# M251_v1 register map
File version: 1.0
Registers are 32-bit, read-write, reset 0x0 unless marked. A register's access mark holds for its fields unless they carry their own. Offsets are from the block's base; [hi:lo] are bit positions; {n}, {i} and the like mark numbered series.

## RTC — RTC Register Map
Base 0x40041000
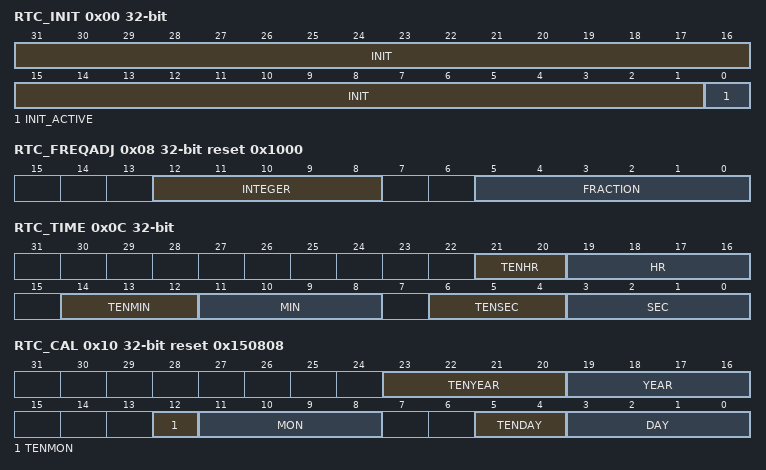
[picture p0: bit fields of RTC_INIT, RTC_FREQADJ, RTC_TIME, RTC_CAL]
0x00 RTC_INIT — RTC Initiation Register
  [31:1] INIT wo — RTC Initiation (Write Only). When RTC block is powered on, RTC is at reset state. User has to write a number (0x a5eb1357) to INIT to make RTC leave reset state. Once the INIT is written as 0xa5eb1357, the RTC will be in un-reset state permanently. The INIT is a write-only field and read value will be always 0.
  [0] INIT_ACTIVE ro — RTC Active Status (Read Only)
    0=RTC is at reset state; 1=RTC is at normal active state
0x08 RTC_FREQADJ reset 0x1000 — RTC Frequency Compensation Register
  [12:8] INTEGER — Integer Part
    {v}=Integer part of detected value is {v+32752} (v=0..31)
  [5:0] FRACTION — Fraction Part. Note: Digit in FCR must be expressed as hexadecimal number.
0x0C RTC_TIME — RTC Time Loading Register
  [21:20] TENHR — 10-Hour Time Digit (0~2)When RTC runs as 12-hour time scale mode, RTC_TIME[21] (the high bit of TENHR[1:0]) means AM/PM indication (If RTC_TIME[21] is 1, it indicates PM time message.)
  [19:16] HR — 1-Hour Time Digit (0~9)
  [14:12] TENMIN — 10-Min Time Digit (0~5)
  [11:8] MIN — 1-Min Time Digit (0~9)
  [6:4] TENSEC — 10-Sec Time Digit (0~5)
  [3:0] SEC — 1-Sec Time Digit (0~9)
0x10 RTC_CAL reset 0x150808 — RTC Calendar Loading Register
  [23:20] TENYEAR — 10-Year Calendar Digit (0~9)
  [19:16] YEAR — 1-Year Calendar Digit (0~9)
  [12] TENMON — 10-Month Calendar Digit (0~1)
  [11:8] MON — 1-Month Calendar Digit (0~9)
  [5:4] TENDAY — 10-Day Calendar Digit (0~3)
  [3:0] DAY — 1-Day Calendar Digit (0~9)
0x14 RTC_CLKFMT reset 0x1 — RTC Time Scale Selection Register
  [0] _24HEN — 24-hour / 12-hour Time Scale Selection. Indicates that RTC_TIME and RTC_TALM are in 24-hour time scale or 12-hour time scale
    0=12-hour time scale with AM and PM indication selected; 1=24-hour time scale selected
0x18 RTC_WEEKDAY reset 0x6 — RTC Day of the Week Register
  [2:0] WEEKDAY — Day of the Week Register
    0=Sunday; 1=Monday; 2=Tuesday; 3=Wednesday; 4=Thursday; 5=Friday; 6=Saturday
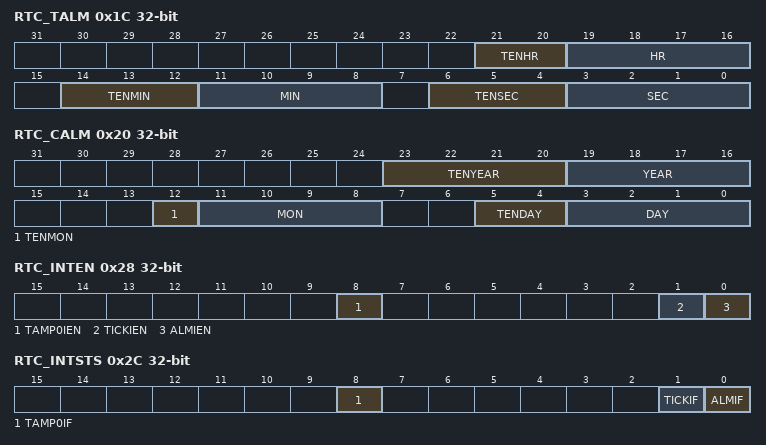
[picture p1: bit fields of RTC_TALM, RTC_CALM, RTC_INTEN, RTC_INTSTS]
0x1C RTC_TALM — RTC Time Alarm Register
  [21:20] TENHR — 10-Hour Time Digit of Alarm Setting (0~2)When RTC runs as 12-hour time scale mode, RTC_TIME[21] (the high bit of TENHR[1:0]) means AM/PM indication (If RTC_TIME[21] is 1, it indicates PM time message.)
  [19:16] HR — 1-Hour Time Digit of Alarm Setting (0~9)
  [14:12] TENMIN — 10-Min Time Digit of Alarm Setting (0~5)
  [11:8] MIN — 1-Min Time Digit of Alarm Setting (0~9)
  [6:4] TENSEC — 10-Sec Time Digit of Alarm Setting (0~5)
  [3:0] SEC — 1-Sec Time Digit of Alarm Setting (0~9)
0x20 RTC_CALM — RTC Calendar Alarm Register
  [23:20] TENYEAR — 10-Year Calendar Digit of Alarm Setting (0~9)
  [19:16] YEAR — 1-Year Calendar Digit of Alarm Setting (0~9)
  [12] TENMON — 10-Month Calendar Digit of Alarm Setting (0~1)
  [11:8] MON — 1-Month Calendar Digit of Alarm Setting (0~9)
  [5:4] TENDAY — 10-Day Calendar Digit of Alarm Setting (0~3)
  [3:0] DAY — 1-Day Calendar Digit of Alarm Setting (0~9)
0x24 RTC_LEAPYEAR ro — RTC Leap Year Indicator Register
  [0] LEAPYEAR — Leap Year Indication (Read Only)
    0=This year is not a leap year; 1=This year is leap year
0x28 RTC_INTEN — RTC Interrupt Enable Register
  [8] TAMP0IEN — Tamper 0 Interrupt Enable Bit. Set TAMP0IEN to 1 can also enable chip wake-up function when tamper 0 interrupt event is generated.
    0=Tamper 0 interrupt Disabled; 1=Tamper 0 interrupt Enabled
  [1] TICKIEN — Time Tick Interrupt Enable Bit. Set TICKIEN to 1 can also enable chip wake-up function when RTC tick interrupt event is generated.
    0=RTC Time Tick interrupt Disabled; 1=RTC Time Tick interrupt Enabled
  [0] ALMIEN — Alarm Interrupt Enable Bit. Set ALMIEN to 1 can also enable chip wake-up function when RTC alarm interrupt event is generated.
    0=RTC Alarm interrupt Disabled; 1=RTC Alarm interrupt Enabled
0x2C RTC_INTSTS — RTC Interrupt Status Register
  [8] TAMP0IF — Tamper 0 Interrupt Flag. Note: Write 1 to clear this bit.
    0=No Tamper 0 interrupt flag is generated; 1=Tamper 0 interrupt flag is generated
  [1] TICKIF — RTC Time Tick Interrupt Flag. Note: Write 1 to clear this bit.
    0=Tick condition did not occur; 1=Tick condition occurred
  [0] ALMIF — RTC Alarm Interrupt Flag. Note: Write 1 to clear this bit.
    0=Alarm condition is not matched; 1=Alarm condition is matched
0x30 RTC_TICK — RTC Time Tick Register
  [2:0] TICK — Time Tick Register. These bits are used to select RTC time tick period for Periodic Time Tick Interrupt request.
    0=Time tick is 1 second; 1=Time tick is 1/2 second; 2=Time tick is 1/4 second; 3=Time tick is 1/8 second; 4=Time tick is 1/16 second; 5=Time tick is 1/32 second; 6=Time tick is 1/64 second; 7=Time tick is 1/128 second
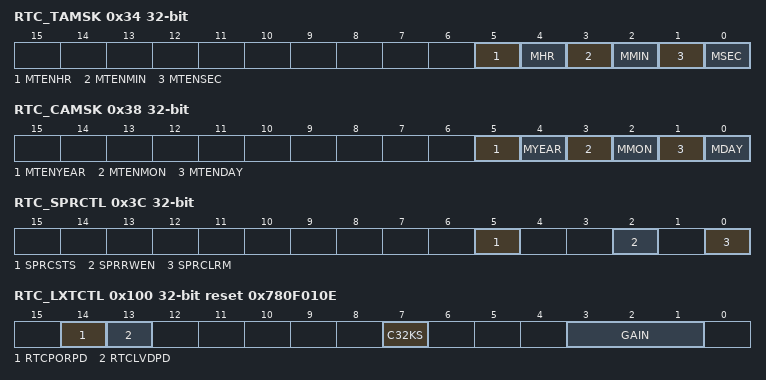
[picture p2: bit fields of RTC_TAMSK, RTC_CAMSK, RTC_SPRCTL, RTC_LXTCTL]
0x34 RTC_TAMSK — RTC Time Alarm Mask Register
  [5] MTENHR — Mask 10-Hour Time Digit of Alarm Setting (0~2)
  [4] MHR — Mask 1-Hour Time Digit of Alarm Setting (0~9)
  [3] MTENMIN — Mask 10-Min Time Digit of Alarm Setting (0~5)
  [2] MMIN — Mask 1-Min Time Digit of Alarm Setting (0~9)
  [1] MTENSEC — Mask 10-Sec Time Digit of Alarm Setting (0~5)
  [0] MSEC — Mask 1-Sec Time Digit of Alarm Setting (0~9)
0x38 RTC_CAMSK — RTC Calendar Alarm Mask Register
  [5] MTENYEAR — Mask 10-Year Calendar Digit of Alarm Setting (0~9)
  [4] MYEAR — Mask 1-Year Calendar Digit of Alarm Setting (0~9)
  [3] MTENMON — Mask 10-Month Calendar Digit of Alarm Setting (0~1)
  [2] MMON — Mask 1-Month Calendar Digit of Alarm Setting (0~9)
  [1] MTENDAY — Mask 10-Day Calendar Digit of Alarm Setting (0~3)
  [0] MDAY — Mask 1-Day Calendar Digit of Alarm Setting (0~9)
0x3C RTC_SPRCTL — RTC Spare Functional Control Register
  [5] SPRCSTS — SPR Clear Flag. This bit indicates if the RTC_SPR0 ~RTC_SPR4 content is cleared when specify tamper event is detected. Note1: Write 1 to clear this bit. Note2: This bit keeps 1 when RTC_INTSTS[8] is not equal to 0.
    0=Spare register content is not cleared; 1=Spare register content is cleared
  [2] SPRRWEN — Spare Register Enable Bit. Note: When spare register is disabled, RTC_SPR0 ~ RTC_SPR4 cannot be accessed.
    0=Spare register Disabled; 1=Spare register Enabled
  [0] SPRCLRM — Spare Register Clear Mask Bit
    0=Spare register will be clear after TAMPER occurs; 1=Spare register will not be clear after TAMPER occurs
{0x40+4i} RTC_SPR{i} (i=0..4) — RTC Spare Register {i}
  [31:0] SPARE — Spare Register. This field is used to store back-up information defined by user. This field will be cleared by hardware automatically once a tamper pin event is detected.
0x100 RTC_LXTCTL reset 0x780F010E — RTC 32.768 KHz Oscillator Control Register
  [14] RTCPORPD — RTC Power on Reset Power Down (Only for VBAT Domain). Note: This bit only can be set to 1.
    0=RTC POR active 1sec after first power up; 1=RTC POR enter power down
  [13] RTCLVDPD — RTC Low Voltage Detector Power Down (Only for VBAT Domain)
    0=RTC Low Voltage Detector active; 1=RTC Low Voltage Detector enter power down
  [7] C32KS — Clock 32K Source Selection:
    0=Internal 32K clock is from 32K crystal; 1=Internal 32K clock is from LIRC32K
  [3:1] GAIN — Oscillator Gain Option. User can select oscillator gain according to crystal external loading and operating temperature range. The larger gain value corresponding to stronger driving capability and higher power consumption. Note: Please refer to the M251 Datasheet for detailed information about LXT electrical characteristics.
    {v}=L{v} mode (v=0..3); {v}=L{v} mode. (Only for VBAT domain) (v=4..7)
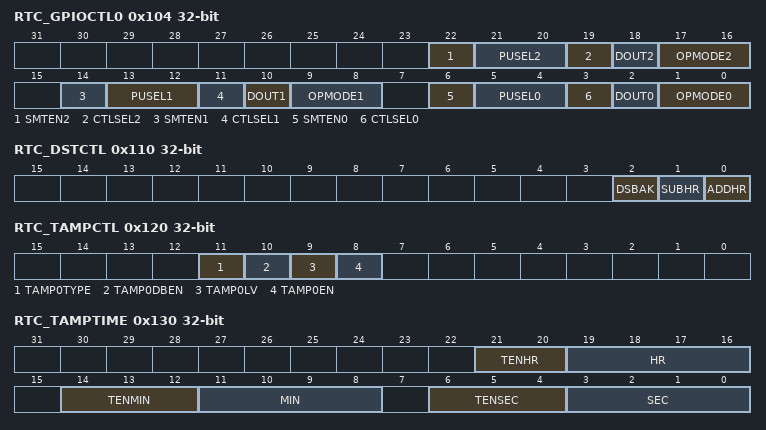
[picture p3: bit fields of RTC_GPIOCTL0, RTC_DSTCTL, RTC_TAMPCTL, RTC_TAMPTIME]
0x104 RTC_GPIOCTL0 — RTC GPIO Control 0 Register
  [22] SMTEN2 — Input Schmitt Trigger Enable Bit (Only for VBAT Domain)
    0=PF.6 input schmitt trigger function Disabled; 1=PF.6 input schmitt trigger function Enabled
  [21:20] PUSEL2 — IO Pull-up and Pull-down Enable Bits (Only for VBAT Domain). Determine PF.6 I/O pull-up or pull-down. The independent pull-up / pull-down control register only valid when OPMODE2 set as input tri-state and open-drain mode and PF6 as tamper pin.
    0=PF.6 pull-up and pull-down disabled; 1=PF.6 pull-up enabled; 2=PF.6 pull-down enabled; 3=PF.6 pull-up and pull-down disabled.Note: Basically, the pull-up control and pull-down control has following behavior limitation
  [19] CTLSEL2 — IO Pin State Backup Selection (Only for VBAT Domain)When TAMP0EN is disabled, PF.6 pin (TAMPER0 pin) can be used as GPIO function. User can program CTLSEL2 to decide PF.6 I/O function is controlled by system power domain GPIO module or VBAT power domain RTC_GPIOCTL0 control register. PF.6 pin function and I/O status are controlled by OPMODE2[1:0] and DOUT2 after CTLSEL2 is set to 1. Note1: CTLSEL2 will automatically be set by hardware to 1 when system power is off and INIT[0] (RTC_INIT[0])] (RTC Active Status) is 1. Note2: The GPIO control feature is not supported when there is not any VBAT power domain.
    0=PF.6 pin I/O function is controlled by GPIO module; 1=PF.6 pin I/O function is controlled by VBAT power domain
  [18] DOUT2 — IO Output Data (Only for VBAT Domain)
    0=PF.6 output low; 1=PF.6 output high
  [17:16] OPMODE2 — IO Operation Mode (Only for VBAT Domain)
    0=PF.6 is input only mode; 1=PF.6 is output push pull mode; 2=PF.6 is open drain mode; 3=PF.6 is quasi-bidirectional mode
  [14] SMTEN1 — Input Schmitt Trigger Enable Bit (Only for VBAT Domain)
    0=PF.5 input schmitt trigger function Disabled; 1=PF.5 input schmitt trigger function Enabled
  [13:12] PUSEL1 — IO Pull-up and Pull-down Enable Bits (Only for VBAT Domain). Determine PF.5 I/O pull-up or pull-down. Note: Basically, the pull-up control and pull-down control has following behavior limitation. The independent pull-up / pull-down control register only valid when OPMODE1 set as input tri-state and open-drain mode.
    0=PF.5 pull-up and pull-down disabled; 1=PF.5 pull-up enabled; 2=PF.5 pull-down enabled; 3=PF.5 pull-up and pull-down disabled
  [11] CTLSEL1 — IO Pin State Backup Selection (Only for VBAT Domain). When low speed 32 kHz oscillator is disabled, PF.5 pin (X32KI pin) can be used as GPIO function. User can program CTLSEL1 to decide PF.5 I/O function is controlled by system power domain GPIO module or VBAT power domain RTC_GPIOCTL0 control register. PF.5 pin function and I/O status are controlled by OPMODE1[1:0] and DOUT1 after CTLSEL1 is set to 1. Note1: CTLSEL1 will automatically be set by hardware to 1 when system power is off and INIT[0] (RTC_INIT[0])] (RTC Active Status) is 1. Note2: The GPIO control feature is not supported when there is not any VBAT power domain.
    0=PF.5 pin I/O function is controlled by GPIO module; 1=PF.5 pin I/O function is controlled by VBAT power domain
  [10] DOUT1 — IO Output Data (Only for VBAT Domain)
    0=PF.5 output low; 1=PF.5 output high
  [9:8] OPMODE1 — IO Operation Mode (Only for VBAT Domain)
    0=PF.5 is input only mode; 1=PF.5 is output push pull mode; 2=PF.5 is open drain mode; 3=PF.5 is quasi-bidirectional mode
  [6] SMTEN0 — Input Schmitt Trigger Enable Bit (Only for VBAT Domain)
    0=PF.4 input schmitt trigger function Disabled; 1=PF.4 input schmitt trigger function Enabled
  [5:4] PUSEL0 — IO Pull-up and Pull-down Enable Bits (Only for VBAT Domain). Determine PF.4 I/O pull-up or pull-down. Note: Basically, the pull-up control and pull-down control has following behavior limitation. The independent pull-up / pull-down control register only valid when OPMODE0 set as input tri-state and open-drain mode.
    0=PF.4 pull-up and pull-down disabled; 1=PF.4 pull-up enabled; 2=PF.4 pull-down enabled; 3=PF.4 pull-up and pull-down disabled
  [3] CTLSEL0 — IO Pin State Backup Selection (Only for VBAT Domain). When low speed 32 kHz oscillator is disabled, PF.4 pin (X32KO pin) can be used as GPIO function. User can program CTLSEL0 to decide PF.4 I/O function is controlled by system power domain GPIO module or VBAT power domain RTC_GPIOCTL0 control register. PF.4 pin function and I/O status are controlled by OPMODE0[1:0] and DOUT0 after CTLSEL0 is set to 1. Note1: CTLSEL0 will automatically be set by hardware to 1 when system power is off and INIT[0] (RTC_INIT[0])] (RTC Active Status) is 1. Note2: The GPIO control feature is not supported when there is not any VBAT power domain.
    0=PF.4 pin I/O function is controlled by GPIO module; 1=PF.4 pin I/O function is controlled by VBAT power domain
  [2] DOUT0 — IO Output Data (Only for VBAT Domain)
    0=PF.4 output low; 1=PF.4 output high
  [1:0] OPMODE0 — IO Operation Mode (Only for VBAT Domain)
    0=PF.4 is input only mode; 1=PF.4 is output push pull mode; 2=PF.4 is open drain mode; 3=PF.4 is quasi-bidirectional mode
0x110 RTC_DSTCTL — RTC Daylight Saving Time Control Register
  [2] DSBAK — Daylight Saving Back
    0=Daylight Saving Change is not performed; 1=Daylight Saving Change is performed
  [1] SUBHR — Subtract 1 Hour
    0=No effect; 1=Indicates RTC hour digit has been subtracted one hour for winter time change
  [0] ADDHR — Add 1 Hour
    0=No effect; 1=Indicates RTC hour digit has been added one hour for summer time change
0x120 RTC_TAMPCTL — RTC Tamper Pin Control Register
  [11] TAMP0TYPE — Tamper 0 DetectType
    0=Tamper as edge detector; 1=Tamper as Level detector
  [10] TAMP0DBEN — Tamper 0 De-bounce Enable Bit. Note: In normal condition (25 ℃), it can deglitch 1~2 ns noise.
    0=Tamper 0 de-bounce Disabled; 1=Tamper 0 de-bounce Enabled., tamper detection pin will sync 1 RTC clock
  [9] TAMP0LV — Tamper 0 Level. This bit depends on level attribute of tamper pin for static tamper detection.
    0=Detect Rising detection, will trigger tamper status when RTC_TAMPCTL[11] = 1; 1=Detect Falling detection, will trigger tamper status when RTC_TAMPCTL[11] = 1
  [8] TAMP0EN — Tamper0 Detect Enable Bit. Note: The reference is RTC-clock. Tamper detector need sync 2 ~ 3 RTC-clock.
    0=Tamper 0 detect Disabled; 1=Tamper 0 detect Enabled
0x130 RTC_TAMPTIME ro — RTC Tamper Time Register
  [21:20] TENHR — 10-Hour Time Digit of TAMPER Time (0~2). Note: 24-hour time scale only.
  [19:16] HR — 1-Hour Time Digit of TAMPER Time (0~9)
  [14:12] TENMIN — 10-Min Time Digit of TAMPER Time (0~5)
  [11:8] MIN — 1-Min Time Digit of TAMPER Time (0~9)
  [6:4] TENSEC — 10-Sec Time Digit of TAMPER Time (0~5)
  [3:0] SEC — 1-Sec Time Digit of TAMPER Time (0~9)
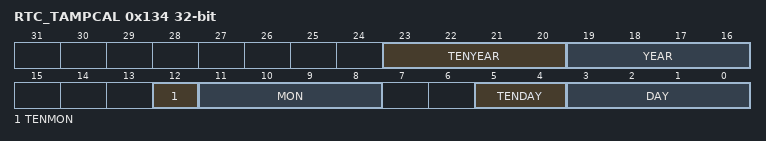
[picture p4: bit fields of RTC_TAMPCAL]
0x134 RTC_TAMPCAL ro — RTC Tamper Calendar Register
  [23:20] TENYEAR — 10-Year Calendar Digit of TAMPER Calendar (0~9)
  [19:16] YEAR — 1-Year Calendar Digit of TAMPER Calendar (0~9)
  [12] TENMON — 10-Month Calendar Digit of TAMPER Calendar (0~1)
  [11:8] MON — 1-Month Calendar Digit of TAMPER Calendar (0~9)
  [5:4] TENDAY — 10-Day Calendar Digit of TAMPER Calendar (0~3)
  [3:0] DAY — 1-Day Calendar Digit of TAMPER Calendar (0~9)
